# SWM241 register map
File version: 1.0
CPU: CM0 r1p0, little endian, 2 interrupt priority bits
Registers are 32-bit, read-write, no defined reset value unless marked. A register's access mark holds for its fields unless they carry their own. Offsets are from the block's base; [hi:lo] are bit positions; lines under a group give offsets from that group; {n}, {i} and the like mark numbered series; 'fields as' and 'values as' point back to an identical list.

## PWM0 — Registers group
Base 0x40046000
Same registers: PWM1 0x40046040, PWM2 0x40046080, PWM3 0x400460C0
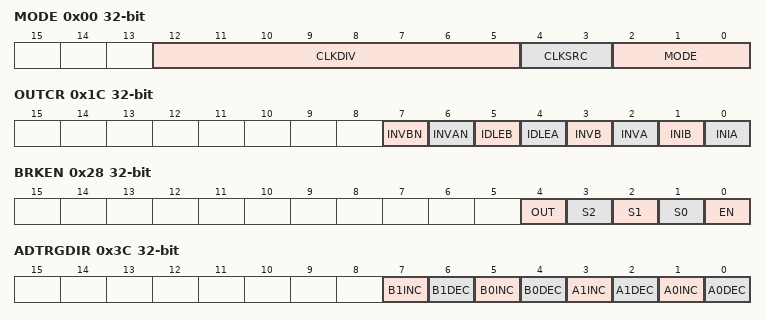
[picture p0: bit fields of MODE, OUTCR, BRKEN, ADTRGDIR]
0x00 MODE
  [12:5] CLKDIV, [4:3] CLKSRC, [2:0] MODE
0x04 PERA
0x08 HIGHA
0x0C DZA
0x10 PERB
0x14 HIGHB
0x18 DZB
0x1C OUTCR
  [7] INVBN, [6] INVAN, [5] IDLEB, [4] IDLEA, [3] INVB, [2] INVA, [1] INIB, [0] INIA
0x20 ADTRGA0
0x24 ADTRGA1
0x28 BRKEN
  [4] OUT, [3] S2, [2] S1, [1] S0, [0] EN
0x2C VALUEA
0x30 VALUEB
0x34 ADTRGB0
0x38 ADTRGB1
0x3C ADTRGDIR
  [7] B1INC, [6] B1DEC, [5] B0INC, [4] B0DEC, [3] A1INC, [2] A1DEC, [1] A0INC, [0] A0DEC

## PWMG — Registers group
Base 0x40046200
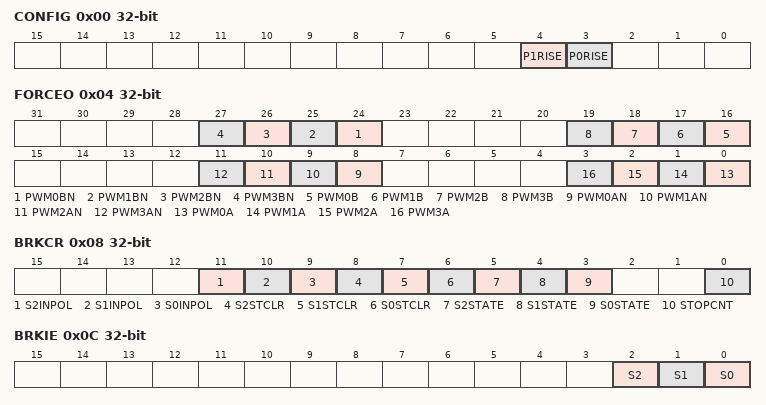
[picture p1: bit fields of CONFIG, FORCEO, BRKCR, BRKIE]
0x00 CONFIG
  [4] P1RISE, [3] P0RISE
0x04 FORCEO
  [n+24] PWM{n}BN (n=0..3), [n+16] PWM{n}B (n=0..3), [n+8] PWM{n}AN (n=0..3), [n] PWM{n}A (n=0..3)
0x08 BRKCR
  [11] S2INPOL, [10] S1INPOL, [9] S0INPOL, [8] S2STCLR, [7] S1STCLR, [6] S0STCLR, [5] S2STATE, [4] S1STATE, [3] S0STATE, [0] STOPCNT
0x0C BRKIE
  [2] S2, [1] S1, [0] S0
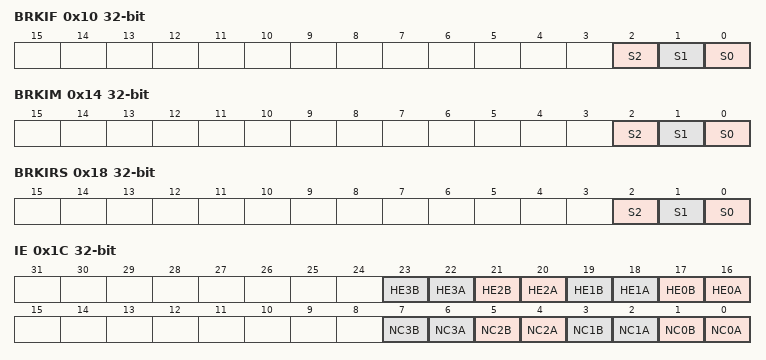
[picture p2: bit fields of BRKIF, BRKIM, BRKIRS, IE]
0x10 BRKIF ro
  [2] S2, [1] S1, [0] S0
0x14 BRKIM
  [2] S2, [1] S1, [0] S0
0x18 BRKIRS
  [2] S2, [1] S1, [0] S0
0x1C IE
  [2n+17] HE{n}B (n=0..3), [2n+16] HE{n}A (n=0..3), [2n+1] NC{n}B (n=0..3), [2n] NC{n}A (n=0..3)
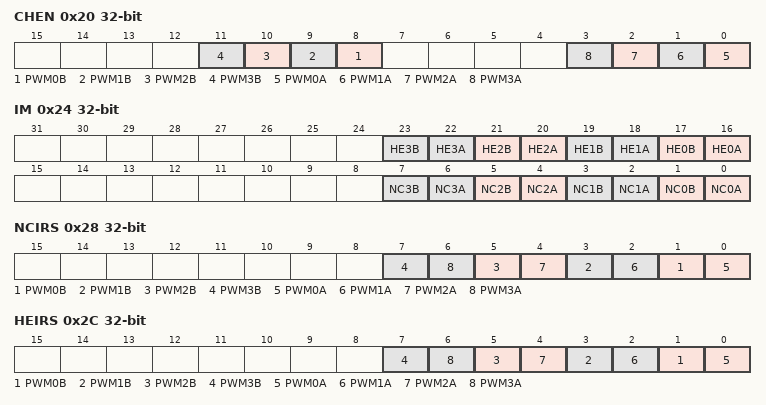
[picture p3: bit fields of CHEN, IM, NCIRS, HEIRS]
0x20 CHEN
  [n+8] PWM{n}B (n=0..3), [n] PWM{n}A (n=0..3)
0x24 IM
  fields as IE
0x28 NCIRS
  [2n+1] PWM{n}B (n=0..3), [2n] PWM{n}A (n=0..3)
0x2C HEIRS
  [2n+1] PWM{n}B (n=0..3), [2n] PWM{n}A (n=0..3)
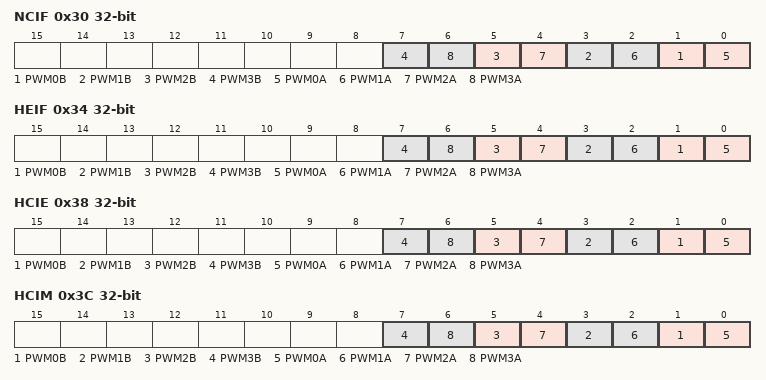
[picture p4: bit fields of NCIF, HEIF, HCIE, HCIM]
0x30 NCIF ro
  [2n+1] PWM{n}B (n=0..3), [2n] PWM{n}A (n=0..3)
0x34 HEIF ro
  [2n+1] PWM{n}B (n=0..3), [2n] PWM{n}A (n=0..3)
0x38 HCIE
  [2n+1] PWM{n}B (n=0..3), [2n] PWM{n}A (n=0..3)
0x3C HCIM
  [2n+1] PWM{n}B (n=0..3), [2n] PWM{n}A (n=0..3)
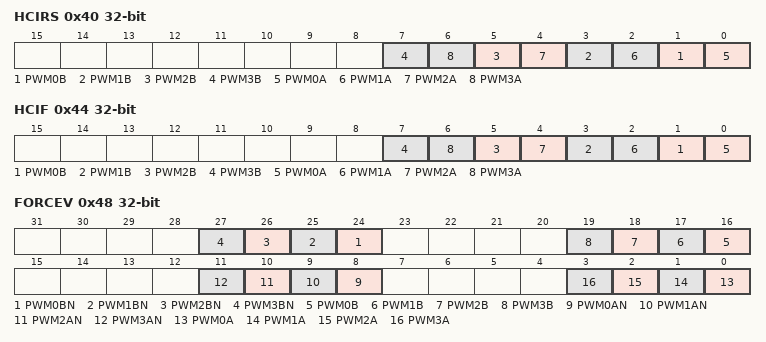
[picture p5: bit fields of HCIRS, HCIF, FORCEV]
0x40 HCIRS
  [2n+1] PWM{n}B (n=0..3), [2n] PWM{n}A (n=0..3)
0x44 HCIF ro
  [2n+1] PWM{n}B (n=0..3), [2n] PWM{n}A (n=0..3)
0x48 FORCEV
  fields as FORCEO

## DMA — Registers group
Base 0x40000800
0x00 EN
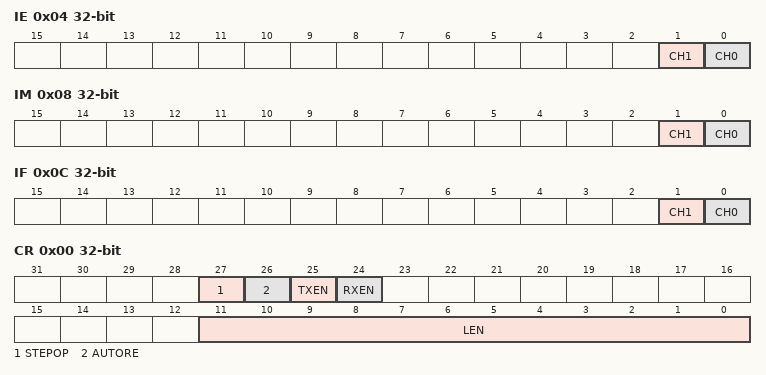
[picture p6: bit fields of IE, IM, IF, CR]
0x04 IE
  [1] CH1, [0] CH0
0x08 IM
  [1] CH1, [0] CH0
0x0C IF
  [1] CH1, [0] CH0
0x10 DSTSGIE
0x14 DSTSGIM
0x18 DSTSGIF
0x1C SRCSGIE
0x20 SRCSGIM
0x24 SRCSGIF
0x3C PRI
0x40 CH0 group — register cluster
  0x00 CR
    [27] STEPOP, [26] AUTORE, [25] TXEN, [24] RXEN, [11:0] LEN
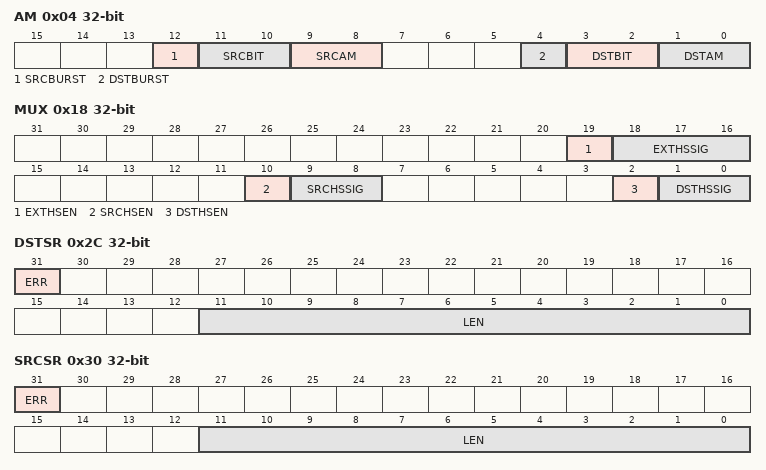
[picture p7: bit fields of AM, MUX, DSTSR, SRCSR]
  0x04 AM
    [12] SRCBURST, [11:10] SRCBIT, [9:8] SRCAM, [4] DSTBURST, [3:2] DSTBIT, [1:0] DSTAM
  0x08 DST
  {0x8+4j} DSTSGADDR{j} (j=1..3)
  0x18 MUX
    [19] EXTHSEN, [18:16] EXTHSSIG, [10] SRCHSEN, [9:8] SRCHSSIG, [2] DSTHSEN, [1:0] DSTHSSIG
  0x1C SRC
  {0x1C+4j} SRCSGADDR{j} (j=1..3)
  0x2C DSTSR ro
    [31] ERR, [11:0] LEN
  0x30 SRCSR ro
    [31] ERR, [11:0] LEN
0x80 CH1 group — register cluster
  0x00 CR
    [27] STEPOP, [26] AUTORE, [25] TXEN, [24] RXEN, [11:0] LEN
  0x04 AM
    fields as CH0.AM
  0x08 DST
  {0x8+4j} DSTSGADDR{j} (j=1..3)
  0x18 MUX
    fields as CH0.MUX
  0x1C SRC
  {0x1C+4j} SRCSGADDR{j} (j=1..3)
  0x2C DSTSR ro
    [31] ERR, [11:0] LEN
  0x30 SRCSR ro
    [31] ERR, [11:0] LEN

## CAN — Registers group
Base 0x400A8000
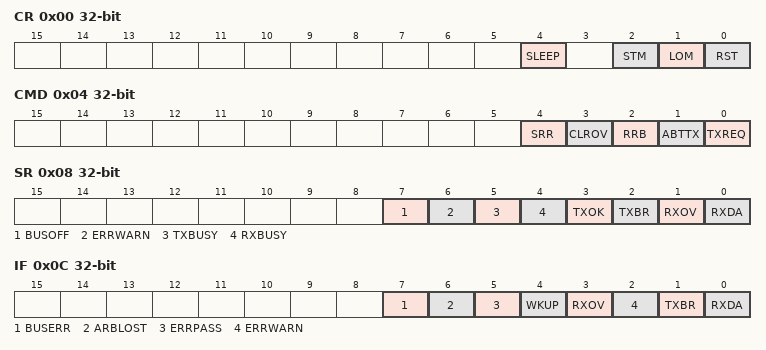
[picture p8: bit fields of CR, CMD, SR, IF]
0x00 CR
  [4] SLEEP, [2] STM, [1] LOM, [0] RST
0x04 CMD wo
  [4] SRR, [3] CLROV, [2] RRB, [1] ABTTX, [0] TXREQ
0x08 SR ro
  [7] BUSOFF, [6] ERRWARN, [5] TXBUSY, [4] RXBUSY, [3] TXOK, [2] TXBR, [1] RXOV, [0] RXDA
0x0C IF
  [7] BUSERR, [6] ARBLOST, [5] ERRPASS, [4] WKUP, [3] RXOV, [2] ERRWARN, [1] TXBR, [0] RXDA
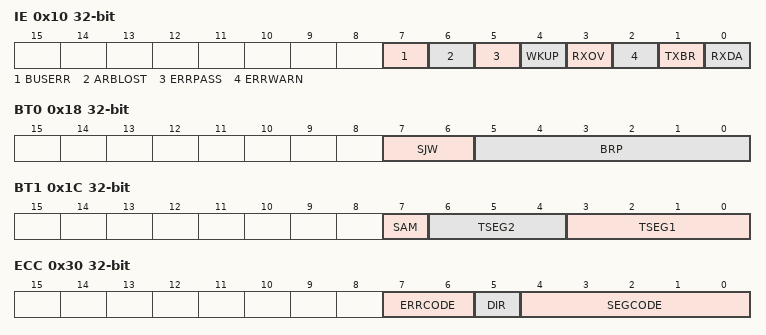
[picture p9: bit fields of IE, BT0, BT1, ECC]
0x10 IE
  fields as IF
0x14 BT2
  [3:0] BRP
0x18 BT0
  [7:6] SJW, [5:0] BRP
0x1C BT1
  [7] SAM, [6:4] TSEG2, [3:0] TSEG1
0x24 AFM
0x28 AFE
0x2C ALC ro
0x30 ECC ro
  [7:6] ERRCODE, [5] DIR, [4:0] SEGCODE
0x34 EWLIM
0x38 RXERR
0x3C TXERR
0x40 FRAME group — register cluster
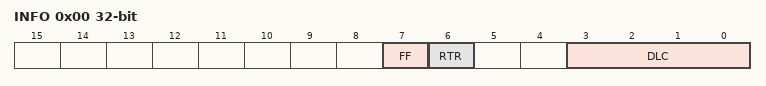
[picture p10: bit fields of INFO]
  0x00 INFO
    [7] FF, [6] RTR, [3:0] DLC
  {0x4+4j} DATA[{j}] (j=0..11)
0x74 RMCNT ro
{0x300+4i} ACR[{i}] (i=0..15)
{0x380+4i} AMR[{i}] (i=0..15)

## FMC — Registers group
Base 0x4004A000
0x00 DATA
0x04 ADDR
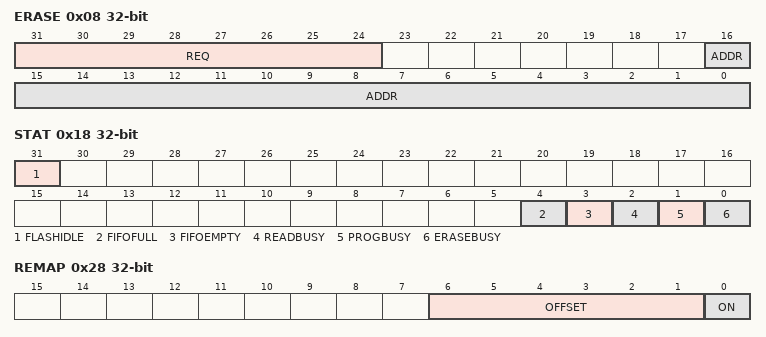
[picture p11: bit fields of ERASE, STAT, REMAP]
0x08 ERASE
  [31:24] REQ, [16:0] ADDR
0x0C PROGEN
0x10 CFG0
0x14 CFG1
0x18 STAT
  [31] FLASHIDLE, [4] FIFOFULL, [3] FIFOEMPTY, [2] READBUSY, [1] PROGBUSY, [0] ERASEBUSY
0x28 REMAP
  [6:1] OFFSET, [0] ON

## WDT — Registers group
Base 0x400A0800
0x00 RSTVAL
0x04 INTVAL
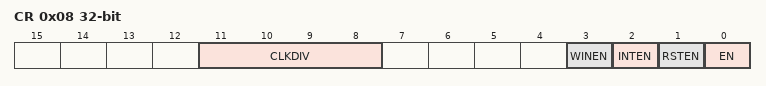
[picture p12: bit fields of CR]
0x08 CR
  [11:8] CLKDIV, [3] WINEN, [2] INTEN, [1] RSTEN, [0] EN
0x0C IF
0x10 FEED

## DIV — Registers group
Base 0x40003800
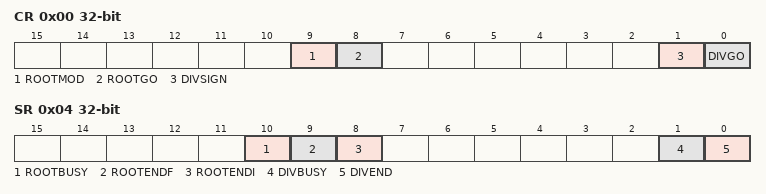
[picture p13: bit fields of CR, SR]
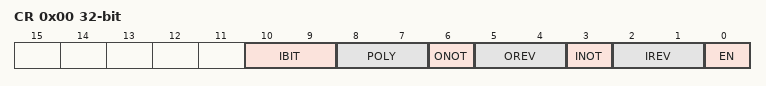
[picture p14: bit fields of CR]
0x00 CR
  [9] ROOTMOD, [8] ROOTGO, [1] DIVSIGN, [0] DIVGO
0x04 SR
  [10] ROOTBUSY, [9] ROOTENDF, [8] ROOTENDI, [1] DIVBUSY, [0] DIVEND
0x10 DIVIDEND
0x14 DIVISOR
0x18 QUO
0x1C REMAIN
0x20 RADICAND
0x24 ROOT

## CRC — Registers group
Base 0x40002800
0x00 CR
  [10:9] IBIT, [8:7] POLY, [6] ONOT, [5:4] OREV, [3] INOT, [2:1] IREV, [0] EN
0x04 DATAIN wo
0x08 INIVAL
0x0C RESULT ro

## RTC — Registers group
Base 0x4004B800
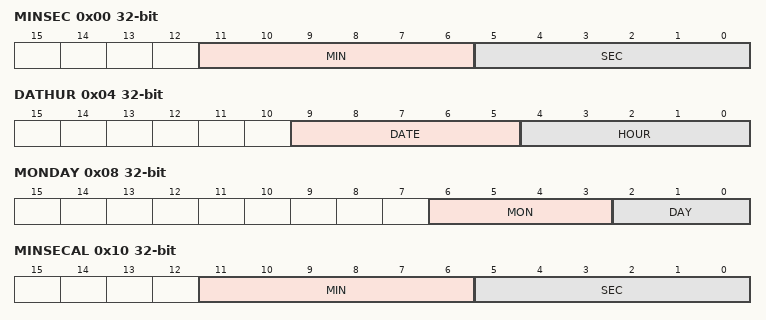
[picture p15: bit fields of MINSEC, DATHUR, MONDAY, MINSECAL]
0x00 MINSEC
  [11:6] MIN, [5:0] SEC
0x04 DATHUR
  [9:5] DATE, [4:0] HOUR
0x08 MONDAY
  [6:3] MON, [2:0] DAY
0x0C YEAR
0x10 MINSECAL
  [11:6] MIN, [5:0] SEC
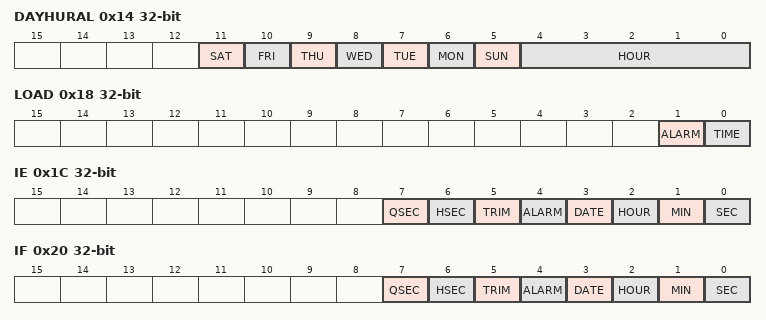
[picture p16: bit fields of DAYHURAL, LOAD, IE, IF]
0x14 DAYHURAL
  [11] SAT, [10] FRI, [9] THU, [8] WED, [7] TUE, [6] MON, [5] SUN, [4:0] HOUR
0x18 LOAD
  [1] ALARM, [0] TIME
0x1C IE
  [7] QSEC, [6] HSEC, [5] TRIM, [4] ALARM, [3] DATE, [2] HOUR, [1] MIN, [0] SEC
0x20 IF
  fields as IE
0x24 EN
0x28 CFGABLE
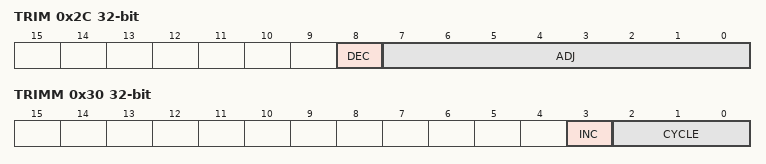
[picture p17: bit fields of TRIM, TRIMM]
0x2C TRIM
  [8] DEC, [7:0] ADJ
0x30 TRIMM
  [3] INC, [2:0] CYCLE
0x60 CALIBREFCNT
0x64 CALIBEN
0x68 CALIBST ro

## SLCD — Registers group
Base 0x400A9800
0x00 CR
  [21:16] CLKDIV, [10] KEYSCAN, [9:8] DRIVSEL, [7:6] SCANFRQ, [5] DUTY, [4] BIAS, [3:2] DISP, [1] SCANEN, [0] DRIVEN
{0x10+4i} DATA[{i}] (i=0..3)

## SLED — Registers group
Base 0x400AA800
0x00 CR
  [31] COMINV, [1] DUTY, [0] EN
0x04 CLKDIV
0x08 TIM
  [25:16] HIGH, [9:0] PERIOD
{0x10+4i} DATA[{i}] (i=0..7)

## SAFETY — Registers group
Base 0x400AB000
0x00 PERWP
  [4] ANACFGR, [3] CLKCFGR, [2] IOCFGR, [1] IER, [0] IAADEN
0x04 RAMWP
  [14:8] ADDR, [1:0] SIZE
0x08 IAACR
  [n] R{n}INT (n=0..3)
0x0C IF
  [n] R{n} (n=0..3)
0x10 IE
  [n] R{n} (n=0..3)
{0x20+8i} REGION{i} group (i=0..3) — register cluster
  0x00 BADDR
  0x04 TADDR
